# STM32F301 register map
File version: 1.9
CPU: CM4 r1p0, little endian, MPU, FPU, 4 interrupt priority bits
Registers are 32-bit, read-write, reset 0x0 unless marked. A register's access mark holds for its fields unless they carry their own. Offsets are from the block's base; [hi:lo] are bit positions.

## PWR — Power control
Base 0x40007000
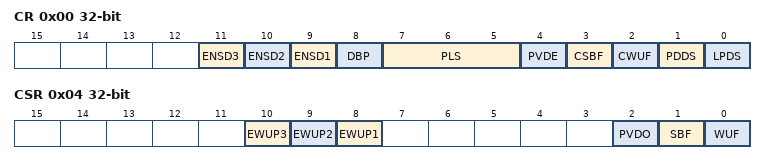
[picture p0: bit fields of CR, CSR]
0x00 CR — power control register
  [11] ENSD3 — ENable SD3 ADC
  [10] ENSD2 — ENable SD2 ADC
  [9] ENSD1 — ENable SD1 ADC
  [8] DBP — Disable backup domain write protection
  [7:5] PLS — PVD level selection
  [4] PVDE — Power voltage detector enable
  [3] CSBF — Clear standby flag
  [2] CWUF — Clear wakeup flag
  [1] PDDS — Power down deepsleep
  [0] LPDS — Low-power deep sleep
0x04 CSR access per field — power control/status register
  [10] EWUP3 rw — Enable WKUP3 pin
  [9] EWUP2 rw — Enable WKUP2 pin
  [8] EWUP1 rw — Enable WKUP1 pin
  [2] PVDO ro — PVD output
  [1] SBF ro — Standby flag
  [0] WUF ro — Wakeup flag

## IWDG — Independent watchdog
Base 0x40003000
0x00 KR 16-bit wo — Key register
  [15:0] KEY — Key value
    0x5555=Unlock (Enable access to PR, RLR and WINR registers); 0xAAAA=Feed watchdog with RLR register value; 0xCCCC=Start the watchdog
0x04 PR 16-bit — Prescaler register
  [2:0] PR — Prescaler divider
    0=DivideBy4 (Divider /4); 1=DivideBy8 (Divider /8); 2=DivideBy16 (Divider /16); 3=DivideBy32 (Divider /32); 4=DivideBy64 (Divider /64); 5=DivideBy128 (Divider /128); other=DivideBy256 (Divider /256)
0x08 RLR 16-bit reset 0xFFF — Reload register
  [11:0] RL — Watchdog counter reload value
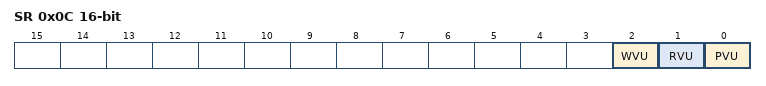
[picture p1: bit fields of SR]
0x0C SR 16-bit ro — Status register
  [2] WVU — Watchdog counter window value update
  [1] RVU — Watchdog counter reload value update
  [0] PVU — Watchdog prescaler value update
0x10 WINR 16-bit reset 0xFFF — Window register
  [11:0] WIN — Watchdog counter window value

## WWDG — Window watchdog
Base 0x40002C00
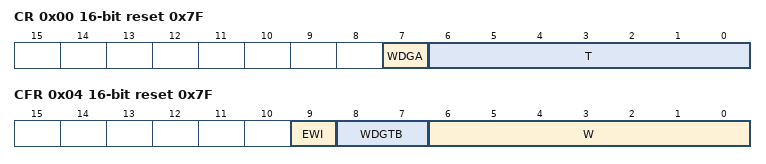
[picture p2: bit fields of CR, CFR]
0x00 CR 16-bit reset 0x7F — Control register
  [7] WDGA — Activation bit
    0=Disabled (Watchdog disabled); 1=Enabled (Watchdog enabled)
  [6:0] T — 7-bit counter
0x04 CFR 16-bit reset 0x7F — Configuration register
  [9] EWI — Early wakeup interrupt
    on write: 1=Enable (interrupt occurs whenever the counter reaches the value 0x40)
  [8:7] WDGTB — Timer base
    0=Div1 (Counter clock (PCLK1 div 4096) div 1); 1=Div2 (Counter clock (PCLK1 div 4096) div 2); 2=Div4 (Counter clock (PCLK1 div 4096) div 4); 3=Div8 (Counter clock (PCLK1 div 4096) div 8)
  [6:0] W — 7-bit window value
0x08 SR 16-bit — Status register
  [0] EWIF write-0-clears — Early wakeup interrupt flag
    on read: 0=Finished (The EWI Interrupt Service Routine has been serviced); 1=Pending (The EWI Interrupt Service Routine has been triggered) | on write: 0=Finished (The EWI Interrupt Service Routine has been serviced)

## TIM6 — Basic timers
Base 0x40001000
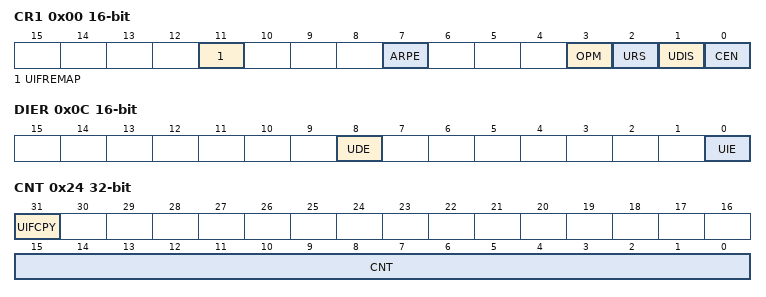
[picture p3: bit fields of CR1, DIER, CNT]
0x00 CR1 16-bit — control register 1
  [11] UIFREMAP — UIF status bit remapping
  [7] ARPE — Auto-reload preload enable
    0=Disabled (TIMx_APRR register is not buffered); 1=Enabled (TIMx_APRR register is buffered)
  [3] OPM — One-pulse mode
    0=Disabled (Counter is not stopped at update event); 1=Enabled (Counter stops counting at the next update event (clearing the CEN bit))
  [2] URS — Update request source
    0=AnyEvent (Any of counter overflow/underflow, setting UG, or update through slave mode, generates an update interrupt or DMA request); 1=CounterOnly (Only counter overflow/underflow generates an update interrupt or DMA request)
  [1] UDIS — Update disable
    0=Enabled (Update event enabled); 1=Disabled (Update event disabled)
  [0] CEN — Counter enable
    0=Disabled (Counter disabled); 1=Enabled (Counter enabled)
0x04 CR2 16-bit — control register 2
  [6:4] MMS — Master mode selection
    0=Reset (Use UG bit from TIMx_EGR register); 1=Enable (Use CNT bit from TIMx_CEN register); 2=Update (Use the update event)
0x0C DIER 16-bit — DMA/Interrupt enable register
  [8] UDE — Update DMA request enable
    0=Disabled (Update DMA request disabled); 1=Enabled (Update DMA request enabled)
  [0] UIE — Update interrupt enable
    0=Disabled (Update interrupt disabled); 1=Enabled (Update interrupt enabled)
0x10 SR 16-bit — status register
  [0] UIF write-0-clears — Update interrupt flag
    on read: 0=NoUpdateOccurred; 1=UpdatePending (Update interrupt pending) | on write: 0=Clear flag
0x14 EGR wo — event generation register
  [0] UG — Update generation
    1=Update (Re-initializes the timer counter and generates an update of the registers.)
0x24 CNT access per field — counter
  [31] UIFCPY ro — UIF Copy
  [15:0] CNT rw — Counter value
0x24 CNT16 16-bit (alternate view of CNT) — 16-bit counter register
  [15:0] CNT — counter value
0x28 PSC 16-bit — prescaler
  [15:0] PSC — Prescaler value
0x2C ARR 16-bit reset 0xFFFF — auto-reload register
  [15:0] ARR — Low Auto-reload value
